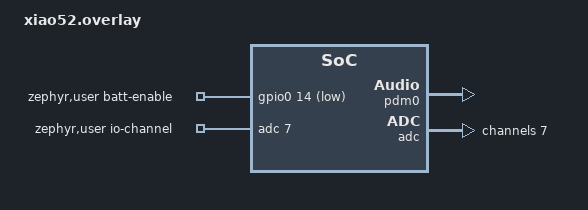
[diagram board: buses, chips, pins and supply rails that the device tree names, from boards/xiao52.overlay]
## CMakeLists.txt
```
cmake_minimum_required(VERSION 3.20.0)

find_package(Zephyr REQUIRED HINTS $ENV{ZEPHYR_BASE})
enable_language(C ASM) # OPUS has ASM

project(omi_device_builder)

# --- Core (always built) ---
target_sources(app PRIVATE
    src/main.c
    src/services/transport.c
    src/services/settings.c
)

# --- Components (gated per feature; see Kconfig) ---
if(CONFIG_OMI_LED)
    target_sources(app PRIVATE src/components/led/led.c)
endif()

if(CONFIG_OMI_MIC)
    target_sources(app PRIVATE src/components/codec/codec.c)
    if(CONFIG_OMI_MIC_BACKEND_ADC)
        target_sources(app PRIVATE src/components/mic/mic_adc.c)
    else()
        target_sources(app PRIVATE src/components/mic/mic_pdm.c)
    endif()
endif()

if(CONFIG_OMI_BATTERY)
    target_sources(app PRIVATE src/components/battery/battery.c)
endif()

if(CONFIG_OMI_BUTTON)
    target_sources(app PRIVATE src/components/button/button.c)
endif()

if(CONFIG_OMI_STORAGE)
    if(CONFIG_OMI_STORAGE_BACKEND_NAND)
        target_sources(app PRIVATE src/components/storage/storage_nand.c)
    else()
        target_sources(app PRIVATE src/components/storage/storage_sd.c)
    endif()
endif()

# Component/service headers are included by short name (e.g. "led.h", "config.h"),
# so expose every module directory (and src/ for shared headers + the vendored
# opus path used as "opus-1.2.1/opus.h") on the include path.
target_include_directories(app PRIVATE
    ${CMAKE_CURRENT_SOURCE_DIR}/src
    ${CMAKE_CURRENT_SOURCE_DIR}/src/components/led
    ${CMAKE_CURRENT_SOURCE_DIR}/src/components/mic
    ${CMAKE_CURRENT_SOURCE_DIR}/src/components/codec
    ${CMAKE_CURRENT_SOURCE_DIR}/src/components/battery
    ${CMAKE_CURRENT_SOURCE_DIR}/src/components/button
    ${CMAKE_CURRENT_SOURCE_DIR}/src/components/storage
    ${CMAKE_CURRENT_SOURCE_DIR}/src/services
)

if(CONFIG_OMI_CODEC_OPUS AND CONFIG_OMI_MIC)
    add_subdirectory(src/opus-1.2.1/)
    target_link_libraries(app PRIVATE opus_codec)
endif()
```

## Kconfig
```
source "Kconfig.zephyr"

menu "Omi Device Builder"

comment "Components — a board's hardware is declared in its devicetree; each"
comment "component below auto-enables when the matching DT node/alias exists."
comment "A contributor adding a board normally only edits the .overlay, not this."

config OMI_MIC
    bool "Microphone capture + codec pipeline"
    default y if $(dt_alias_enabled,dmic-dev)
    help
      Microphone capture (feeds the Opus codec + BLE audio stream). Auto-on when
      the board devicetree provides a `dmic-dev` alias (a PDM mic). Turn OFF for
      boards whose mic has no Zephyr driver yet (analog/ESP32 PDM) so the
      firmware still builds as a BLE-only device.

choice OMI_MIC_BACKEND
    prompt "Microphone backend"
    depends on OMI_MIC
    default OMI_MIC_BACKEND_PDM if $(dt_alias_enabled,dmic-dev)
    default OMI_MIC_BACKEND_ADC
    help
      Which driver implements the mic. PDM uses the Zephyr dmic subsystem;
      Analog samples an ADC channel (for analog MEMS mics like the MG24's).

config OMI_MIC_BACKEND_PDM
    bool "PDM (Zephyr dmic)"
    help
      Digital PDM mic via the Zephyr dmic subsystem. Needs a `dmic-dev` alias.

config OMI_MIC_BACKEND_ADC
    bool "Analog (ADC sampling)"
    help
      Analog MEMS mic sampled over ADC. Skeleton only — not implemented yet.

endchoice

config OMI_CODEC_OPUS
    bool "Opus audio codec"
    default y
    help
      Opus audio codec, wire-compatible with the Omi app. The Opus encoder is
      only compiled when OMI_MIC is also on (see CMakeLists), but the codec
      framing constants (CODEC_ID, packet size) are part of the BLE audio
      protocol and are kept available even on BLE-only boards.

config OMI_LED
    bool "Status LED"
    default y if $(dt_compat_enabled,gpio-leds) || $(dt_compat_enabled,pwm-leds)
    help
      Status LED (connection/advertising indication). Auto-on when the board has
      a `gpio-leds` or `pwm-leds` node.

config OMI_BATTERY
    bool "Battery monitoring"
    default y
    help
      Battery voltage (ADC divider) + BLE Battery Service. Enabled by default;
      set =n on boards without battery sensing. (TODO: auto-detect once battery
      moves to a `voltage-divider` devicetree node.)

config OMI_BUTTON
    bool "User button"
    default y if $(dt_alias_enabled,sw0)
    help
      User button (long-press power off). Auto-on when the board devicetree
      provides an `sw0` alias (see overlays/<board>.overlay).

config OMI_STORAGE
    bool "Mass storage (SD card / external NAND flash)"
    default y if $(dt_nodelabel_enabled,sdmmc_disk) || $(dt_nodelabel_enabled,omi_storage)
    help
      Mount a mass-storage backend as a filesystem at /omi. Auto-on when the
      board devicetree provides an SD disk (nodelabel `sdmmc_disk`) or an
      external-flash littlefs partition (nodelabel `omi_storage`).
      (Nodelabels are used instead of compatibles because Kconfig can't pass a
      comma-containing compatible like `zephyr,sdmmc-disk`.)

choice OMI_STORAGE_BACKEND
    prompt "Storage backend"
    depends on OMI_STORAGE
    default OMI_STORAGE_BACKEND_SD if $(dt_nodelabel_enabled,sdmmc_disk)
    default OMI_STORAGE_BACKEND_NAND

config OMI_STORAGE_BACKEND_SD
    bool "SD card (FATFS)"
    select DISK_ACCESS
    select DISK_DRIVER_SDMMC
    select FILE_SYSTEM
    select FAT_FILESYSTEM_ELM
    help
      FATFS on an SD card via disk_access. Needs a `zephyr,sdmmc-disk` node.

config OMI_STORAGE_BACKEND_NAND
    bool "External flash (littlefs)"
    select FLASH
    select FLASH_MAP
    select FILE_SYSTEM
    select FILE_SYSTEM_LITTLEFS
    help
      littlefs on an external flash chip. Needs a flash node (e.g. `spi-nand`)
      with a fixed-partition labelled `omi_storage`.

endchoice

config OMI_STORAGE_SD_DISK_NAME
    string "SD disk-name (must match the devicetree node's disk-name)"
    depends on OMI_STORAGE_BACKEND_SD
    default "SD"

comment "Minimum recommended for a functional device: OMI_MIC + OMI_LED."
comment "BLE-only placeholder boards (no mic/LED driver yet) may disable both."

endmenu
```

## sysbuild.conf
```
# Sysbuild: build MCUboot alongside the application (only used when building
# with `west build --sysbuild`; the plain build_all path ignores this).
SB_CONFIG_BOOTLOADER_MCUBOOT=y
```

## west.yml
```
# west manifest for omi-device-builder.
#
# T2 ("application") topology: THIS repo is the manifest repo, and it imports
# Zephyr (which in turn pulls every vendor HAL module — hal_nordic, hal_espressif,
# hal_silabs — needed for the XIAO nRF / ESP32-S3 / MG24 targets).
#
# Setup (see README "Setup" section):
#   west init -l omi-device-builder
#   west update
#
manifest:
  version: "1.0"

  remotes:
    - name: zephyrproject-rtos
      url-base: https://github.com/zephyrproject-rtos

  projects:
    - name: zephyr
      remote: zephyrproject-rtos
      # Pinned to a fixed release for reproducible builds.
      revision: v4.4.1
      import: true

  self:
    path: omi-device-builder
```

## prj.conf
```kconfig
# ---- Omi Device Builder: common configuration ----
# Everything board-specific lives in boards/<board>/ (<board>.{conf,overlay}, and
# ota.overlay/mcuboot.overlay for the OTA build)
# and set CONFIG_BT_DEVICE_NAME="omi-<device>".

# --- App features ---
# Components (mic/led/battery/button/codec) auto-enable from the board's
# devicetree via Kconfig defaults; override per board in boards/<board>.conf.

# --- Drivers ---
CONFIG_GPIO=y
CONFIG_ADC=y
CONFIG_AUDIO=y
CONFIG_AUDIO_DMIC=y
CONFIG_REGULATOR=y
CONFIG_POWEROFF=y

# --- Bluetooth (peripheral, audio streaming) ---
CONFIG_BT=y
CONFIG_BT_PERIPHERAL=y
CONFIG_BT_DEVICE_NAME="omi-xiao"
CONFIG_BT_DEVICE_APPEARANCE=832
CONFIG_BT_DIS=y
CONFIG_BT_DIS_FW_REV=y
CONFIG_BT_DIS_FW_REV_STR="1.0.0"
CONFIG_BT_BAS=y
CONFIG_BT_SMP=y
CONFIG_BT_SETTINGS=y
CONFIG_SETTINGS=y
CONFIG_BT_GATT_DYNAMIC_DB=y

# --- BLE throughput (2M PHY + DLE + large MTU), host-side (SoC-agnostic) ---
# Controller-specific knobs (CONFIG_BT_CTLR_*) live in the Nordic board confs
# so non-Nordic SoCs (ESP32S3, MG24) still build.
CONFIG_BT_USER_PHY_UPDATE=y
CONFIG_BT_AUTO_PHY_UPDATE=y
CONFIG_BT_USER_DATA_LEN_UPDATE=y
CONFIG_BT_DATA_LEN_UPDATE=y
CONFIG_BT_GATT_CLIENT=y
CONFIG_BT_L2CAP_TX_MTU=498
CONFIG_BT_BUF_ACL_TX_SIZE=251
CONFIG_BT_BUF_ACL_RX_SIZE=251
CONFIG_BT_BUF_ACL_TX_COUNT=10
CONFIG_BT_BUF_EVT_RX_COUNT=12
CONFIG_BT_CONN_TX_MAX=10
CONFIG_BT_L2CAP_TX_BUF_COUNT=10
CONFIG_BT_ATT_TX_COUNT=10

# --- System ---
CONFIG_SERIAL=y
CONFIG_LOG=y
CONFIG_LOG_DEFAULT_LEVEL=3
CONFIG_CBPRINTF_FP_SUPPORT=y
CONFIG_MAIN_STACK_SIZE=4096
CONFIG_SYSTEM_WORKQUEUE_STACK_SIZE=2048
CONFIG_HEAP_MEM_POOL_SIZE=8192
```

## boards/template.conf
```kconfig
# Board template — copy to boards/<yourboard>.conf.
#
# Most components auto-enable from the devicetree (see <yourboard>.overlay), so
# this file usually only needs the BLE name. Add overrides here when the DT
# can't express your intent.

# Required: the BLE advertised name (artifact becomes omi-<yourboard>).
CONFIG_BT_DEVICE_NAME="omi-yourboard"

# --- Optional overrides ---

# Analog mic (no PDM): select the ADC backend and skip the dmic-dev alias.
# CONFIG_OMI_MIC_BACKEND_ADC=y

# Force a component off even though the hardware exists (e.g. bring-up):
# CONFIG_OMI_BATTERY=n
# CONFIG_OMI_BUTTON=n

# SD disk name (must match the devicetree sdmmc-disk `disk-name`):
# CONFIG_OMI_STORAGE_SD_DISK_NAME="SD"

# BLE-only placeholder board (mic/LED driver not ready yet):
# CONFIG_OMI_MIC=n
# CONFIG_OMI_LED=n

# --- Nordic (BT_LL_SW_SPLIT) controller throughput knobs, if applicable ---
# CONFIG_BT_CTLR_DATA_LENGTH_MAX=251
# CONFIG_BT_CTLR_PHY_2M=y
# CONFIG_BT_CTLR_TX_PWR_PLUS_8=y
```

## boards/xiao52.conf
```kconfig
# Seeed XIAO nRF52840 (Sense)  ->  board: xiao_ble/nrf52840/sense
CONFIG_BT_DEVICE_NAME="omi-xiao52"

# nRF (BT_LL_SW_SPLIT) controller throughput knobs
CONFIG_BT_CTLR_DATA_LENGTH_MAX=251
CONFIG_BT_CTLR_PHY_2M=y
CONFIG_BT_CTLR_TX_PWR_PLUS_8=y
```

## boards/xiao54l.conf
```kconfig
# Seeed XIAO nRF54L15  ->  board: xiao_nrf54l15/nrf54l15/cpuapp
# TODO(verify): confirm the exact board target name in your NCS version
# (e.g. `west boards | grep xiao`). Adjust scripts/build_all.* accordingly.
CONFIG_BT_DEVICE_NAME="omi-xiao54l"

# nRF (BT_LL_SW_SPLIT) controller throughput knobs
CONFIG_BT_CTLR_DATA_LENGTH_MAX=251
CONFIG_BT_CTLR_PHY_2M=y
```

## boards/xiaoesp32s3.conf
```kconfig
# Seeed XIAO ESP32S3 Sense  ->  board: xiao_esp32s3/esp32s3/procpu
CONFIG_BT_DEVICE_NAME="omi-xiaoesp32s3"

# ESP32-S3 PDM mic has no Zephyr driver yet -> build BLE-only for now.
CONFIG_OMI_ENABLE_MIC=n

# The ESP32 BT controller requires Espressif binary blobs
# (`west blobs fetch hal_espressif`). Until those are present, build the BT HCI
# driver WITHOUT blobs so the image still compiles.
# NOTE: this is a build-only config — BLE will NOT work on real hardware until
# you fetch the blobs and remove this line.
CONFIG_BUILD_ONLY_NO_BLOBS=y

# XIAO ESP32S3 has a single user LED (not RGB) -> disable the RGB status LED.
CONFIG_OMI_ENABLE_LED=n

# ESP32-S3 uses its own BLE controller (NOT the Nordic BT_LL_SW_SPLIT), so no
# CONFIG_BT_CTLR_* knobs here; 2M PHY / DLE are requested by the host at runtime.
#
# TODO(verify) before building:
#   1. Fetch Espressif blobs:  west blobs fetch hal_espressif
#   2. Confirm your Zephyr has a PDM/DMIC driver for ESP32-S3 and wire the
#      `dmic-dev` alias to it in boards/xiaoesp32s3.overlay (the S3 Sense mic is
#      a PDM MSM261D3526H1CPM). If no dmic driver exists, mic capture needs an
#      I2S-PDM-RX shim.
#   3. Confirm battery-sense ADC channel/divider for your board revision.
```

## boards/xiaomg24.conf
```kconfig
# Seeed XIAO MG24 (Sense)  ->  board: xiao_mg24 (Silicon Labs EFR32MG24)
# TODO(verify): confirm the exact board target in your Zephyr:
#   west boards | grep mg24     (e.g. xiao_mg24/efr32mg24b220f1536im48)
CONFIG_BT_DEVICE_NAME="omi-xiaomg24"

# Mic is analog (needs an ADC backend, not DMIC) -> build BLE-only for now.
CONFIG_OMI_ENABLE_MIC=n

# EFR32MG24 uses the Silicon Labs BLE controller (NOT the Nordic BT_LL_SW_SPLIT),
# so no CONFIG_BT_CTLR_* knobs here. 2M PHY / DLE are requested by the host at
# runtime; the Silabs controller advertises its own buffer limits.
#
# TODO(verify): confirm your Zephyr enables the Silabs BLE controller for this
# board (CONFIG_BT + hci_silabs).
# MIC: the XIAO MG24 Sense mic (MSM381ACT001) is ANALOG (DATA=PC9, PWR=PC8), not
# PDM — it needs a 16 kHz ADC-sampling backend, not the DMIC src/mic.c. See
# boards/xiaomg24.overlay.

# XIAO MG24 has a single user LED (not RGB) -> disable the RGB status LED.
# TODO(verify): if your board revision exposes an RGB LED, re-enable and add the
# pwmleds nodes in boards/xiaomg24.overlay.
CONFIG_OMI_ENABLE_LED=n
```

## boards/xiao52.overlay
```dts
/*
 * Seeed XIAO nRF52840 Sense overlay.
 *
 * The board DTS already defines the mic (&pdm0 + MSM261 power regulator on
 * P1.10), the RGB gpio-LEDs (led0/led1/led2), and the ADC. We only:
 *   1. expose the mic as the `dmic-dev` alias and enable it,
 *   2. keep the mic power regulator on at boot,
 *   3. add a battery-sense ADC channel (AIN7 = P0.31, divider read-enable P0.14).
 */

#include <zephyr/dt-bindings/adc/adc.h>
#include <zephyr/dt-bindings/adc/nrf-saadc.h>

/ {
	aliases {
		dmic-dev = &pdm0;
	};

	/* Power the on-board MSM261 PDM mic at boot (regulator on P1.10). */
	msm261d3526hicpm-c-en {
		regulator-boot-on;
	};

	zephyr,user {
		io-channels = <&adc 7>;
		batt-enable-gpios = <&gpio0 14 GPIO_ACTIVE_LOW>;
	};
};

&pdm0 {
	status = "okay";
};

&adc {
	#address-cells = <1>;
	#size-cells = <0>;

	channel@7 {
		reg = <7>;
		zephyr,gain = "ADC_GAIN_1_6";
		zephyr,reference = "ADC_REF_INTERNAL";
		zephyr,acquisition-time = <ADC_ACQ_TIME(ADC_ACQ_TIME_MICROSECONDS, 10)>;
		zephyr,input-positive = <NRF_SAADC_AIN7>; /* P0.31 */
		zephyr,resolution = <12>;
	};
};
```

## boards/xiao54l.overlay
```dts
/*
 * Seeed XIAO nRF54L15 overlay.
 *
 * The board DTS already defines the mic (&pdm20 as nodelabel `dmic_dev`, with
 * pins + the `pdm_imu_pwr` regulator on P0.01, regulator-boot-on) and a single
 * gpio LED (led0). We only need to expose the mic under the `dmic-dev` alias
 * that src/mic.c looks up.
 *
 * Battery: the board has a `vbat_pwr` enable but no ready ADC channel here; add a
 * zephyr,user io-channels entry (like xiao52) once you know the sense pin.
 */

/ {
	aliases {
		dmic-dev = &pdm20;
	};
};
```

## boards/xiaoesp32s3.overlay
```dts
/*
 * Seeed XIAO ESP32S3 Sense — onboard PDM mic (MSM261D3526H1CPM).
 * Schematic pins (Seeed wiki):
 *     PDM CLK  -> GPIO42
 *     PDM DIN  -> GPIO41
 *
 * BLOCKER (why there is no dmic-dev node here):
 *   Zephyr v4.4.1 has NO PDM/DMIC driver for the ESP32-S3. The esp32 I2S driver
 *   (`espressif,esp32-i2s`) does not implement PDM-RX, and no `zephyr,dmic`
 *   backend exists for this SoC. A devicetree overlay can only bind pins to an
 *   existing driver, so the mic cannot be enabled here yet.
 *
 * To support the mic, a Zephyr driver is needed first, e.g.:
 *   - extend drivers/i2s/i2s_esp32.c with PDM-RX mode, then use the mpxxdtyy
 *     (PDM-over-I2S) DMIC driver on top, OR
 *   - write a DMIC driver wrapping ESP-IDF's I2S-PDM API.
 * Once such a driver + binding exist, add its node here (CLK=42, DIN=41) and the
 * `dmic-dev` alias that src/mic.c looks up.
 */
```

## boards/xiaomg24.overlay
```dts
/*
 * Seeed XIAO MG24 Sense — onboard mic is the MSM381ACT001, an ANALOG MEMS mic
 * (NOT a PDM/digital mic). Schematic pins (Seeed wiki / makerguides):
 *     MIC_DATA (analog output) -> PC9   (sample via EFR32 IADC/ADC)
 *     MIC_PWR  (enable)        -> PC8
 *
 * BLOCKER (why there is no dmic-dev node here):
 *   The mic is analog, so it is not a DMIC/PDM device — the Zephyr DMIC API used
 *   by src/mic.c does not apply at all. Capturing it requires a 16 kHz
 *   ADC-sampling backend (timer-triggered IADC into a PCM buffer), plus the
 *   Silabs ADC driver. That is an application-code path to add, not an overlay.
 *
 * To support the mic:
 *   1. add a mic backend that samples PC9 via the ADC at 16 kHz (mono, 16-bit),
 *      feeding codec_receive_pcm() the same way src/mic.c does,
 *   2. drive MIC_PWR (PC8) high to power the mic,
 *   3. select that ADC backend for this board instead of the DMIC src/mic.c.
 */
```

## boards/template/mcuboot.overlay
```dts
/*
 * OPTIONAL — only needed if this board supports the OTA build (scripts/build_ota.*).
 * MCUBOOT image: link MCUboot into boot_partition. Partition sizes live in
 * partitions.dtsi (shared with ota.overlay).
 */

#include "partitions.dtsi"

/ {
	chosen {
		zephyr,code-partition = &boot_partition;
	};
};
```

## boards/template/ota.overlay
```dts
/*
 * OPTIONAL — only needed if this board supports the OTA build (scripts/build_ota.*).
 * APPLICATION image: link the app into slot0. The partition sizes live in
 * partitions.dtsi (shared with mcuboot.overlay). Delete these three files if the
 * board has no OTA support.
 */

#include "partitions.dtsi"

/ {
	chosen {
		zephyr,code-partition = &slot0_partition;
	};
};
```

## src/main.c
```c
#include <zephyr/kernel.h>
#include <zephyr/logging/log.h>

#include "config.h"
#include "led.h"
#include "settings.h"
#include "transport.h"
#ifdef CONFIG_OMI_MIC
#include "codec.h"
#include "mic.h"
#endif
#ifdef CONFIG_OMI_BATTERY
#include "battery.h"
#endif
#ifdef CONFIG_OMI_STORAGE
#include "storage.h"
#endif

LOG_MODULE_REGISTER(main, CONFIG_LOG_DEFAULT_LEVEL);

/* Shared state referenced by transport.c. */
bool is_connected = false;
bool is_charging = false;

#ifdef CONFIG_OMI_BATTERY
extern uint8_t battery_percentage;
#endif

#ifdef CONFIG_OMI_MIC
/* Opus-encoded frame ready -> queue for BLE notification. */
static void codec_handler(uint8_t *data, size_t len)
{
    (void) broadcast_audio_packets(data, len);
}

/* PCM frame from the mic -> feed the codec. Frame length is the agreed
 * MIC_FRAME_SAMPLES (the mix_handler carries no length). */
static void mic_handler(int16_t *buffer)
{
    int err = codec_receive_pcm(buffer, MIC_FRAME_SAMPLES);
    if (err) {
        LOG_ERR("codec_receive_pcm failed: %d", err);
    }
}
#endif

#ifdef CONFIG_OMI_LED
/* Simple status LED: solid blue when connected, blinking red while advertising. */
static void led_status_loop(void)
{
    bool blink = false;
    while (1) {
        if (is_connected) {
            set_led_red(false);
            set_led_blue(true);
        } else {
            set_led_blue(false);
            set_led_red(blink);
            blink = !blink;
        }
        k_msleep(500);
    }
}
K_THREAD_DEFINE(led_tid, 1024, led_status_loop, NULL, NULL, NULL, K_PRIO_PREEMPT(10), 0, 0);
#endif

int main(void)
{
    LOG_INF("omi-device-builder starting (%s)", CONFIG_BT_DEVICE_NAME);

    app_settings_init();

#ifdef CONFIG_OMI_STORAGE
    if (storage_init()) {
        LOG_ERR("storage_init failed");
    }
#endif

#ifdef CONFIG_OMI_LED
    led_start();
#endif

#ifdef CONFIG_OMI_MIC
    /* Audio pipeline: mic -> codec -> transport. */
    set_codec_callback(codec_handler);
    if (codec_start()) {
        LOG_ERR("codec_start failed");
    }

    set_mic_callback(mic_handler);
    mic_set_gain(app_settings_get_mic_gain());
    if (mic_start()) {
        LOG_ERR("mic_start failed");
    }
#else
    LOG_WRN("Mic disabled for this board (no Zephyr driver yet) - BLE only, no audio");
#endif

    if (transport_start()) {
        LOG_ERR("transport_start failed");
    }

    LOG_INF("omi-device-builder ready");
    return 0;
}
```

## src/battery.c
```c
#include "battery.h"

#include <zephyr/drivers/adc.h>
#include <zephyr/drivers/gpio.h>
#include <zephyr/kernel.h>
#include <zephyr/logging/log.h>

LOG_MODULE_REGISTER(battery, CONFIG_LOG_DEFAULT_LEVEL);

/* Battery ADC channel comes from the board overlay's zephyr,user node:
 *   / { zephyr,user { io-channels = <&adc CH>; }; };
 * The on-board resistor divider ratio must be set per board (see overlay /
 * BATTERY_DIVIDER_* below). */
#if DT_NODE_HAS_PROP(DT_PATH(zephyr_user), io_channels)
#define HAS_BATTERY_ADC 1
static const struct adc_dt_spec batt_adc = ADC_DT_SPEC_GET(DT_PATH(zephyr_user));
#endif

/* Optional GPIO to enable the battery-measurement divider (Xiao nRF52840:
 * P0.14 low = enable read). Provided via the "batt-enable-gpios" property on
 * zephyr,user if present. */
#if DT_NODE_HAS_PROP(DT_PATH(zephyr_user), batt_enable_gpios)
#define HAS_BATTERY_ENABLE 1
static const struct gpio_dt_spec batt_enable = GPIO_DT_SPEC_GET(DT_PATH(zephyr_user), batt_enable_gpios);
#endif

/* Resistor-divider multiplier: Vbatt = Vadc * (R1 + R2) / R2.
 * Default 2.0 (x1000 fixed point). Override per board with BATTERY_DIVIDER_NUM/DEN
 * in the board .conf via CFLAGS if the divider differs. */
#ifndef BATTERY_DIVIDER_MILLI
#define BATTERY_DIVIDER_MILLI 2000
#endif

int battery_charge_start(void)
{
#ifdef HAS_BATTERY_ADC
    if (!adc_is_ready_dt(&batt_adc)) {
        LOG_ERR("Battery ADC not ready");
        return -ENODEV;
    }
    int ret = adc_channel_setup_dt(&batt_adc);
    if (ret) {
        LOG_ERR("adc_channel_setup failed: %d", ret);
        return ret;
    }
#ifdef HAS_BATTERY_ENABLE
    if (gpio_is_ready_dt(&batt_enable)) {
        gpio_pin_configure_dt(&batt_enable, GPIO_OUTPUT_ACTIVE);
    }
#endif
    LOG_INF("Battery ADC ready");
    return 0;
#else
    LOG_WRN("No battery ADC channel configured for this board");
    return 0;
#endif
}

int battery_get_millivolt(uint16_t *battery_millivolt)
{
#ifdef HAS_BATTERY_ADC
    int16_t sample = 0;
    struct adc_sequence sequence = {
        .buffer = &sample,
        .buffer_size = sizeof(sample),
    };
    int ret = adc_sequence_init_dt(&batt_adc, &sequence);
    if (ret) {
        return ret;
    }
    ret = adc_read_dt(&batt_adc, &sequence);
    if (ret) {
        return ret;
    }

    int32_t mv = sample;
    ret = adc_raw_to_millivolts_dt(&batt_adc, &mv);
    if (ret) {
        return ret;
    }

    mv = (mv * BATTERY_DIVIDER_MILLI) / 1000;
    *battery_millivolt = (uint16_t) mv;
    return 0;
#else
    *battery_millivolt = 0;
    return -ENOTSUP;
#endif
}

int battery_get_percentage(uint8_t *battery_percentage, uint16_t battery_millivolt)
{
    /* Coarse single-cell LiPo curve. */
    static const struct {
        uint16_t mv;
        uint8_t pct;
    } curve[] = {
        {4200, 100}, {4100, 90}, {4000, 80}, {3900, 70}, {3800, 60}, {3700, 45},
        {3600, 25},  {3500, 12}, {3400, 5},  {3300, 0},
    };

    if (battery_millivolt >= curve[0].mv) {
        *battery_percentage = 100;
        return 0;
    }
    for (size_t i = 0; i < ARRAY_SIZE(curve) - 1; i++) {
        if (battery_millivolt <= curve[i].mv && battery_millivolt > curve[i + 1].mv) {
            /* Linear interpolate between points. */
            uint16_t span_mv = curve[i].mv - curve[i + 1].mv;
            uint8_t span_pct = curve[i].pct - curve[i + 1].pct;
            *battery_percentage = curve[i + 1].pct + ((battery_millivolt - curve[i + 1].mv) * span_pct) / span_mv;
            return 0;
        }
    }
    *battery_percentage = 0;
    return 0;
}
```

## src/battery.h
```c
#ifndef BATTERY_H
#define BATTERY_H

#include <stdint.h>

/** Initialize and start battery measurement. */
int battery_charge_start(void);

/** Read battery voltage in millivolts. */
int battery_get_millivolt(uint16_t *battery_millivolt);

/** Convert millivolts to a 0-100% estimate (single-cell LiPo). */
int battery_get_percentage(uint8_t *battery_percentage, uint16_t battery_millivolt);

#endif // BATTERY_H
```

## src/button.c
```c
#include "button.h"

#include <zephyr/drivers/gpio.h>
#include <zephyr/kernel.h>
#include <zephyr/logging/log.h>
#include <zephyr/sys/poweroff.h>

LOG_MODULE_REGISTER(button, CONFIG_LOG_DEFAULT_LEVEL);

/* User button from devicetree alias sw0 (gpio-keys). Optional: if the board
 * has no sw0, this compiles out gracefully. */
#if DT_NODE_EXISTS(DT_ALIAS(sw0))
#define HAS_BUTTON 1
static const struct gpio_dt_spec button = GPIO_DT_SPEC_GET(DT_ALIAS(sw0), gpios);
static struct gpio_callback button_cb;

#define LONG_PRESS_MS 2000
static int64_t press_started_ms;

static void button_pressed(const struct device *dev, struct gpio_callback *cb, uint32_t pins)
{
    ARG_UNUSED(dev);
    ARG_UNUSED(cb);
    ARG_UNUSED(pins);

    int val = gpio_pin_get_dt(&button);
    if (val > 0) {
        press_started_ms = k_uptime_get();
    } else if (press_started_ms != 0) {
        int64_t held = k_uptime_get() - press_started_ms;
        press_started_ms = 0;
        LOG_INF("Button released after %lld ms", held);
        if (held >= LONG_PRESS_MS) {
            turnoff_all();
        }
    }
}
#endif

int button_init(void)
{
#ifdef HAS_BUTTON
    if (!gpio_is_ready_dt(&button)) {
        LOG_ERR("Button GPIO not ready");
        return -ENODEV;
    }
    int ret = gpio_pin_configure_dt(&button, GPIO_INPUT);
    if (ret) {
        return ret;
    }
    ret = gpio_pin_interrupt_configure_dt(&button, GPIO_INT_EDGE_BOTH);
    if (ret) {
        return ret;
    }
    gpio_init_callback(&button_cb, button_pressed, BIT(button.pin));
    gpio_add_callback(button.port, &button_cb);
    LOG_INF("Button initialized");
    return 0;
#else
    LOG_INF("No user button on this board");
    return 0;
#endif
}

void activate_button_work(void)
{
    /* Button uses GPIO interrupts directly; nothing extra to start. */
}

void register_button_service(void)
{
    /* No BLE button service in this build. */
}

void turnoff_all(void)
{
    LOG_INF("Powering off");
    k_msleep(100);
    sys_poweroff();
}
```

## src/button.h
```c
#ifndef BUTTON_H
#define BUTTON_H

/** Configure the user button GPIO. */
int button_init(void);

/** Start button handling (work/callbacks). */
void activate_button_work(void);

/** Register a BLE button service (no-op stub in this build). */
void register_button_service(void);

/** Power the device off (button long-press / critical battery). */
void turnoff_all(void);

#endif // BUTTON_H
```

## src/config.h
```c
#ifndef CONFIG_H
#define CONFIG_H

// Audio / ring-buffer sizing (kept identical to the omi firmware so the codec
// and the BLE audio packet framing stay wire-compatible with the Omi app).
#define AUDIO_BUFFER_SAMPLES 16000 // 1s @ 16 kHz
#define NETWORK_RING_BUF_SIZE 32   // number of frames * CODEC_OUTPUT_MAX_BYTES
#define MINIMAL_PACKET_SIZE 100    // below this it's not worth sending anything

// Microphone
#define MIC_SAMPLE_RATE 16000
#define MIC_CHANNELS 1
// Samples per captured PCM frame handed to the mic callback (100 ms @ 16 kHz).
// The mic callback signature carries no length, so mic.c and the consumer
// (main.c) must agree on this constant.
#define MIC_FRAME_SAMPLES (MIC_SAMPLE_RATE / 10)

// Codec
#ifdef CONFIG_OMI_CODEC_OPUS
#define CODEC_OPUS 1
#else
#error "Enable CONFIG_OMI_CODEC_OPUS in the project .conf file"
#endif

#if CODEC_OPUS
#define CODEC_PACKAGE_SAMPLES (160 * 2)
#define CODEC_OUTPUT_MAX_BYTES (CODEC_PACKAGE_SAMPLES / 2)
#define CODEC_OPUS_APPLICATION OPUS_APPLICATION_RESTRICTED_LOWDELAY
#define CODEC_OPUS_BITRATE 32000
#define CODEC_OPUS_VBR 1
#define CODEC_OPUS_COMPLEXITY 3
#endif
#define CONFIG_OPUS_MODE CONFIG_OPUS_MODE_CELT

// Codec ID advertised on the audio-format characteristic (21 = Opus).
#ifdef CODEC_OPUS
#define CODEC_ID 21
#endif

#endif // CONFIG_H
```

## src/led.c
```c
#include "led.h"

#include <zephyr/drivers/pwm.h>
#include <zephyr/logging/log.h>

#include "settings.h"
#include "utils.h"

LOG_MODULE_REGISTER(led, CONFIG_LOG_DEFAULT_LEVEL);

/* Each board overlay provides led_red / led_green / led_blue PWM nodelabels.
 * The Xiao boards expose an onboard RGB LED (active-low); the overlay maps
 * these to PWM channels. */
static const struct pwm_dt_spec led_red = PWM_DT_SPEC_GET(DT_NODELABEL(led_red));
static const struct pwm_dt_spec led_green = PWM_DT_SPEC_GET(DT_NODELABEL(led_green));
static const struct pwm_dt_spec led_blue = PWM_DT_SPEC_GET(DT_NODELABEL(led_blue));

int led_start(void)
{
    ASSERT_TRUE(pwm_is_ready_dt(&led_red));
    ASSERT_TRUE(pwm_is_ready_dt(&led_green));
    ASSERT_TRUE(pwm_is_ready_dt(&led_blue));
    LOG_INF("LEDs (PWM) started");
    return 0;
}

static void set_led_on_off(const struct pwm_dt_spec *led, bool on)
{
    if (!pwm_is_ready_dt(led)) {
        return;
    }
    uint32_t pulse_width_ns = 0;
    if (on) {
        uint8_t ratio = app_settings_get_dim_ratio();
        if (ratio > 100) {
            ratio = 100;
        }
        pulse_width_ns = (led->period * ratio) / 100;
    }
    pwm_set_pulse_dt(led, pulse_width_ns);
}

void set_led_red(bool on)
{
    set_led_on_off(&led_red, on);
}

void set_led_green(bool on)
{
    set_led_on_off(&led_green, on);
}

void set_led_blue(bool on)
{
    set_led_on_off(&led_blue, on);
}

void set_led_pwm(led_color_t color, uint8_t level)
{
    const struct pwm_dt_spec *led;
    switch (color) {
    case LED_RED:
        led = &led_red;
        break;
    case LED_GREEN:
        led = &led_green;
        break;
    case LED_BLUE:
        led = &led_blue;
        break;
    default:
        return;
    }
    if (!pwm_is_ready_dt(led)) {
        return;
    }
    if (level > 100) {
        level = 100;
    }
    pwm_set_pulse_dt(led, (led->period * level) / 100);
}

void led_off(void)
{
    set_led_red(false);
    set_led_green(false);
    set_led_blue(false);
}
```

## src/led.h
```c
#ifndef LED_H
#define LED_H

#include <stdbool.h>
#include <stdint.h>

typedef enum {
    LED_RED,
    LED_GREEN,
    LED_BLUE
} led_color_t;

int led_start(void);
void set_led_red(bool on);
void set_led_green(bool on);
void set_led_blue(bool on);
void set_led_pwm(led_color_t color, uint8_t level);
void led_off(void);

#endif // LED_H
```

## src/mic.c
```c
#include "mic.h"

#include <zephyr/audio/dmic.h>
#include <zephyr/kernel.h>
#include <zephyr/logging/log.h>

#include <hal/nrf_pdm.h>

#include "config.h"

/* nRF PDM hardware gain (register value, not dB). Range 0x00 (-20 dB) ..
 * 0x28 (0 dB, reset default) .. 0x50 (+20 dB). The Zephyr dmic driver leaves
 * this at the 0 dB default, which is too quiet for the onboard MSM261 mic. */
#define MIC_PDM_GAIN 0x50 /* +20 dB, tune down if loud sounds clip */

LOG_MODULE_REGISTER(mic, CONFIG_LOG_DEFAULT_LEVEL);

/* TEMP DEBUG: log captured PCM amplitude (peak/mean) ~once per second so we can
 * tell real audio from silence/noise. Set to 0 to disable. */
#define MIC_LEVEL_DEBUG 0

/* Standard Zephyr DMIC (nRF PDM) device. Each board overlay must provide a
 * `dmic-dev` alias pointing at its PDM peripheral (with the mic pins wired via
 * pinctrl and status = "okay"). */
static const struct device *const dmic_dev = DEVICE_DT_GET(DT_ALIAS(dmic_dev));

/* 100 ms blocks @ 16 kHz mono, 16-bit = 1600 samples = 3200 bytes. */
#define MIC_BLOCK_SAMPLES MIC_FRAME_SAMPLES
#define MIC_BLOCK_BYTES (MIC_BLOCK_SAMPLES * sizeof(int16_t))
#define MIC_BLOCK_COUNT 8

K_MEM_SLAB_DEFINE_STATIC(mic_mem_slab, MIC_BLOCK_BYTES, MIC_BLOCK_COUNT, 4);

static mix_handler _callback = NULL;
static volatile bool _running = false;
static uint8_t _gain = 4; /* neutral (see mic_set_gain) */

K_THREAD_STACK_DEFINE(mic_stack, 2048);
static struct k_thread mic_thread;

void set_mic_callback(mix_handler callback)
{
    _callback = callback;
}

void mic_set_gain(uint8_t gain_level)
{
    if (gain_level > 8) {
        gain_level = 8;
    }
    _gain = gain_level;
    LOG_INF("Mic gain level set to %u", gain_level);
}

bool mic_is_running(void)
{
    return _running;
}

/* Apply software gain around the neutral level 4 (=1x). Each step is ~ +/-25%.
 * Kept simple and saturating; hardware PDM has no analog gain we can retune. */
static void apply_gain(int16_t *samples, size_t count)
{
    if (_gain == 4) {
        return;
    }
    for (size_t i = 0; i < count; i++) {
        int32_t v = (int32_t) samples[i] * (int32_t) _gain / 4;
        if (v > INT16_MAX) {
            v = INT16_MAX;
        } else if (v < INT16_MIN) {
            v = INT16_MIN;
        }
        samples[i] = (int16_t) v;
    }
}

static void mic_entry(void *a, void *b, void *c)
{
    ARG_UNUSED(a);
    ARG_UNUSED(b);
    ARG_UNUSED(c);

    while (_running) {
        void *buffer;
        uint32_t size;
        int ret = dmic_read(dmic_dev, 0, &buffer, &size, 1000);
        if (ret < 0) {
            LOG_ERR("dmic_read failed: %d", ret);
            continue;
        }

        int16_t *pcm = (int16_t *) buffer;
        size_t count = size / sizeof(int16_t);
        apply_gain(pcm, count);

#if MIC_LEVEL_DEBUG
        {
            static uint32_t dbg_ctr;
            int32_t peak = 0;
            int64_t sum_abs = 0;
            for (size_t i = 0; i < count; i++) {
                int32_t a = pcm[i] < 0 ? -(int32_t) pcm[i] : (int32_t) pcm[i];
                if (a > peak) {
                    peak = a;
                }
                sum_abs += a;
            }
            if ((dbg_ctr++ % 10) == 0) { /* ~1 Hz (blocks are 100 ms) */
                LOG_INF("mic level: peak=%d mean_abs=%d s0=%d s1=%d n=%u",
                        (int) peak,
                        (int) (count ? sum_abs / (int64_t) count : 0),
                        pcm[0],
                        count > 1 ? pcm[1] : 0,
                        (unsigned) count);
            }
        }
#endif

        if (_callback) {
            /* omi's mix_handler passes a pointer; the codec path consumes a
             * fixed MIC_BLOCK; keep parity with the original contract. */
            _callback(pcm);
        }

        k_mem_slab_free(&mic_mem_slab, buffer);
    }
}

int mic_start(void)
{
    if (!device_is_ready(dmic_dev)) {
        LOG_ERR("DMIC device not ready");
        return -ENODEV;
    }

    struct pcm_stream_cfg stream = {
        .pcm_width = 16,
        .mem_slab = &mic_mem_slab,
    };

    struct dmic_cfg cfg = {
        .io =
            {
                /* Typical PDM mic timing; adjust per mic datasheet if needed. */
                .min_pdm_clk_freq = 1000000,
                .max_pdm_clk_freq = 3500000,
                .min_pdm_clk_dc = 40,
                .max_pdm_clk_dc = 60,
            },
        .streams = &stream,
        .channel =
            {
                .req_num_streams = 1,
                .req_num_chan = MIC_CHANNELS,
            },
    };

    cfg.channel.req_chan_map_lo = dmic_build_channel_map(0, 0, PDM_CHAN_LEFT);
    stream.pcm_rate = MIC_SAMPLE_RATE;
    stream.block_size = MIC_BLOCK_BYTES;

    int ret = dmic_configure(dmic_dev, &cfg);
    if (ret < 0) {
        LOG_ERR("dmic_configure failed: %d", ret);
        return ret;
    }

    /* The Zephyr dmic driver configures the PDM at 0 dB gain, which is too
     * quiet for this board's mic. Bump the PDM hardware gain directly via the
     * nrfx HAL (persists across start; the driver never rewrites it). */
    nrf_pdm_gain_set((NRF_PDM_Type *) DT_REG_ADDR(DT_ALIAS(dmic_dev)), MIC_PDM_GAIN, MIC_PDM_GAIN);
    LOG_INF("PDM gain set to 0x%02x", MIC_PDM_GAIN);

    ret = dmic_trigger(dmic_dev, DMIC_TRIGGER_START);
    if (ret < 0) {
        LOG_ERR("dmic_trigger START failed: %d", ret);
        return ret;
    }

    _running = true;
    k_thread_create(&mic_thread,
                    mic_stack,
                    K_THREAD_STACK_SIZEOF(mic_stack),
                    mic_entry,
                    NULL,
                    NULL,
                    NULL,
                    K_PRIO_PREEMPT(5),
                    0,
                    K_NO_WAIT);
    k_thread_name_set(&mic_thread, "mic");

    LOG_INF("PDM mic started (%d Hz, %d ch)", MIC_SAMPLE_RATE, MIC_CHANNELS);
    return 0;
}
```

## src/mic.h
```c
#ifndef MIC_H
#define MIC_H

#include <stdbool.h>
#include <stdint.h>

typedef void (*mix_handler)(int16_t *);

/**
 * @brief Start PDM microphone capture.
 *
 * Uses the Zephyr DMIC (nRF PDM) driver via the `dmic_dev` devicetree node.
 * Captured 16 kHz / 16-bit mono PCM is delivered to the callback registered
 * with set_mic_callback() (or forwarded to the codec if none is set).
 *
 * @return 0 on success, negative errno on error.
 */
int mic_start(void);

void set_mic_callback(mix_handler callback);

/** Software gain (0..8), applied to the PCM samples before encoding. */
void mic_set_gain(uint8_t gain_level);

bool mic_is_running(void);

#endif // MIC_H
```

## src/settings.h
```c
#ifndef SETTINGS_H
#define SETTINGS_H

#include <stdint.h>

/** Initialize app settings (defaults). */
int app_settings_init(void);

int app_settings_save_dim_ratio(uint8_t new_ratio);
uint8_t app_settings_get_dim_ratio(void);

int app_settings_save_mic_gain(uint8_t new_gain);
uint8_t app_settings_get_mic_gain(void);

#endif // SETTINGS_H
```

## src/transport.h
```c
#ifndef TRANSPORT_H
#define TRANSPORT_H

#include <stddef.h>
#include <stdint.h>

#ifdef CONFIG_OMI_ENABLE_BATTERY
extern uint8_t battery_percentage;
#endif

/** Initialize BLE (services + advertising + audio pusher thread). */
int transport_start(void);

/** Turn BLE fully off. */
int transport_off(void);

/** Queue one encoded audio frame for BLE notification. */
int broadcast_audio_packets(uint8_t *buffer, size_t size);

/** Current BLE connection, or NULL. */
struct bt_conn *get_current_connection(void);

/** Move the active link to low-power (slow) or fast streaming params. */
void transport_conn_set_lowpower(bool low);

#endif // TRANSPORT_H
```
